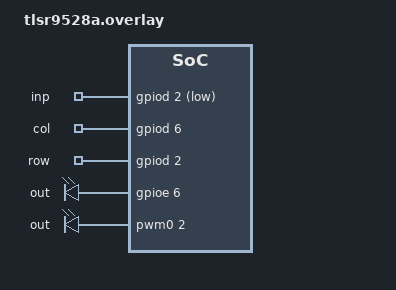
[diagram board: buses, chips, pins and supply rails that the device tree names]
/ {
	/* Short TL_Key3 (J5 pin 13) to ground (J3 pin 24, 26, 28, 30) */
	key_pool {
		compatible = "gpio-keys";

		inp {
			gpios = <&gpiod 2 (GPIO_ACTIVE_LOW | GPIO_PULL_UP)>,
					<&gpiod 7 (GPIO_ACTIVE_LOW | GPIO_PULL_UP)>;
		};
	};

	key_matrix {
		compatible = "gpio-keys";

		col {
			gpios = <&gpiod 6 GPIO_ACTIVE_HIGH>,
					<&gpiof 6 GPIO_ACTIVE_HIGH>;
		};

		row {
			gpios = <&gpiod 2 (GPIO_PULL_DOWN | GPIO_ACTIVE_HIGH)>,
					<&gpiod 7 (GPIO_PULL_DOWN | GPIO_ACTIVE_HIGH)>;
		};
	};

	led_pool {
		compatible = "gpio-leds";

		out {
			gpios = <&gpioe 6 GPIO_ACTIVE_HIGH>;
		};
	};

	pwm_pool {
		compatible = "pwm-leds";
		out {
			pwms = <&pwm0 2 PWM_MSEC(20) PWM_POLARITY_NORMAL>,
					<&pwm0 0 PWM_MSEC(20) PWM_POLARITY_NORMAL>,
					<&pwm0 1 PWM_MSEC(20) PWM_POLARITY_NORMAL>;
		};
	};
};

&pwm0 {
	/* On board RGB LEDs */
	pinctrl-ch0 = <&pwm_ch0_pe7_default>;
	pinctrl-ch2 = <&pwm_ch1_pd1_default>;
	pinctrl-ch1 = <&pwm_ch2_pd0_default>;
};

&pinctrl {
	pwm_ch0_pe7_default: pwm_ch0_pe7_default {
		pinmux = <B9x_PINMUX_SET(B9x_PORT_E, B9x_PIN_7, B92_FUNC_PWM0)>;
	};
	pwm_ch1_pd1_default: pwm_ch1_pd1_default {
		pinmux = <B9x_PINMUX_SET(B9x_PORT_D, B9x_PIN_1, B92_FUNC_PWM1)>;
	};
	pwm_ch2_pd0_default: pwm_ch2_pd0_default {
		pinmux = <B9x_PINMUX_SET(B9x_PORT_D, B9x_PIN_0, B92_FUNC_PWM2)>;
	};
};

